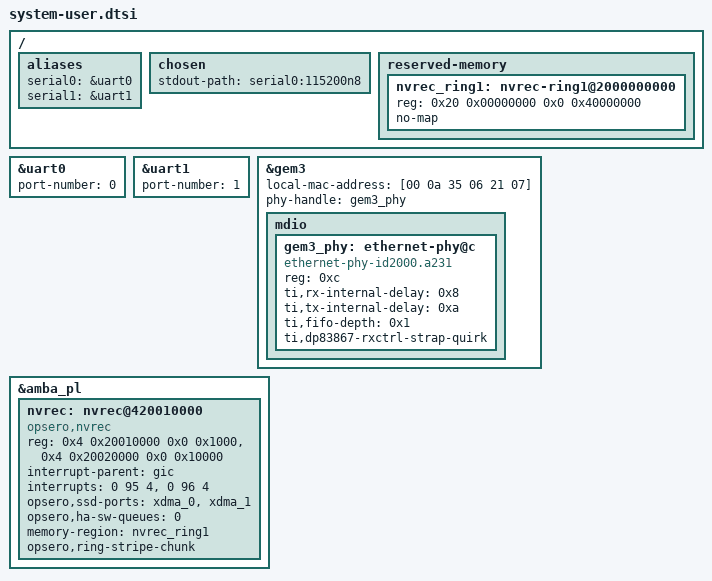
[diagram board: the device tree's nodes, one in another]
// SPDX-License-Identifier: MIT
// Copyright (C) 2025-2026, Opsero Electronic Design Inc.  All rights reserved.

/*
 * SoC-side board fixups, layered on top of the gen-machineconf /
 * lopper-generated cortexa53-linux.dts (which already carries the PS config
 * and the PL xilinx_xdma PCIe node(s) from the XSA).
 *
 * UART (ttyPS console):
 *   The 2025.2 lopper/gen-machineconf flow emits port-number = <0> on BOTH
 *   uart0 (ff000000) and uart1 (ff010000), so the ttyPS0/ttyPS1 assignment is
 *   left to probe order. This board's console is on psu_uart_0, so pin the
 *   port numbers (and serial aliases) explicitly. Mirrors the PetaLinux BSPs.
 *
 * Note: unlike the ZCU104, this board's SD interface sustains UHS modes (the
 * PetaLinux BSP needs no sdhci cap), so no SD override is applied here.
 */

&uart0 {
   port-number = <0>;
};

&uart1 {
   port-number = <1>;
};

/ {
   aliases {
      serial0 = &uart0;
      serial1 = &uart1;
   };
   chosen {
      stdout-path = "serial0:115200n8";
   };
};

/* PS GEM3 (board RJ45): the SDT flow does not describe the board-level
 * TI DP83867 PHY, so Linux falls back to the Generic PHY driver and the
 * RGMII clock delays are never programmed - the link negotiates 1G but
 * passes no packets. Values from the official zynqmp-zcu106-revA.dts
 * (PHY at MDIO address 0xc). The fixed MAC replaces the random one the
 * SDT flow leaves us with, keeping DHCP leases stable across boots.
 */
&gem3 {
	local-mac-address = [00 0a 35 06 21 07];
	phy-handle = <&gem3_phy>;
	mdio {
		#address-cells = <1>;
		#size-cells = <0>;
		gem3_phy: ethernet-phy@c {
			compatible = "ethernet-phy-id2000.a231";
			reg = <0xc>;
			ti,rx-internal-delay = <0x8>;
			ti,tx-internal-delay = <0xa>;
			ti,fifo-depth = <0x1>;
			ti,dp83867-rxctrl-strap-quirk;
		};
	};
};

/*
 * FPGA Drive NVMe-offload recorder: the nvrec kernel driver (Yocto/meta-nvrec,
 * sw/nvrec-driver) drives nvrec_core AND the NVMe Host Accelerator through ONE
 * node, so the addresses of both IPs are listed here (include/nvrec_regs.h,
 * zcu106_hpc0 address map):
 *   core     nvrec_core registers           0x4_2001_0000, 4 KB
 *   ha-lite  nvmeha S_AXI_LITE registers    0x4_2002_0000, 64 KB
 *   irq core nvrec_core irq   pl_ps_irq0[6] -> GIC SPI 95
 *   irq ha   ha_interrupt     pl_ps_irq0[7] -> GIC SPI 96
 * The SDT also emits generic nodes for the two IPs (no Linux driver binds
 * them). opsero,ssd-ports lists the PL root ports in SSD order: xdma_0 =
 * SSD1 = nvmeha SSD 0, xdma_1 = SSD2 = nvmeha SSD 1; an NVMe SSD behind any
 * other root port is left to the stock nvme driver.
 * The Host Accelerator is built with HARDWARE-ONLY queues (register map 1.0
 * rev b: no S_AXI software queue window, the hardware SQ/CQ is NVMe QID 1,
 * all CPU I/O goes through the nvrec command injector):
 * opsero,ha-sw-queues = <0> says so explicitly.
 * The other nvmeha build parameters and the queue window come from nvrec_regs.h;
 * the opsero,ha-* properties (driver.md) override them without a rebuild.
 * If the block design changes the address map or the interrupt bits, change
 * this node with it.
 *
 * Split ring (register map 1.3, driver 1.2): nvrec_core's second ring port
 * reaches the soldered 2 GB PL DDR4 through a DDR4 controller in the PL, at
 * 0x20_0000_0000, mapped for the ring port and the XDMA root ports only --
 * the PS has no path to it and no memory node covers it. memory-region
 * reserves its first 1 GB for ring B (no-map: the kernel never maps or
 * allocates it); ring A stays in the CMA pool (cma=, PS DDR4). The driver
 * refuses a split ring while the controller is not calibrated
 * (STATE.MEM1_READY). opsero,ring-stripe-chunk makes the board's default
 * stripe the whole chunk (driver module parameter stripe_kb and the apps'
 * --stripe override it): measured on this board (Sabrent RAID0, Gen3 x4), whole
 * chunks play back best (5500 MB/s sustained vs 5250 with 4 KB / 64 KB stripes;
 * 6000 at MaxPayload 256) and record 6000 MB/s at MaxPayload 256, while 64 KB
 * was the worst layout in every SSD playback test. The in-order ring
 * writer/reader alternates between HP2 (~5.15 GB/s) and the PL DDR4 (~7.8
 * GB/s), so any stripe sits near their harmonic mean (~6.2 GB/s); whole chunks
 * keep each SSD command in one memory.
 */
/ {
   reserved-memory {
      #address-cells = <2>;
      #size-cells = <2>;
      ranges;

      nvrec_ring1: nvrec-ring1@2000000000 {
         reg = <0x20 0x00000000 0x0 0x40000000>;
         no-map;
      };
   };
};

&amba_pl {
   nvrec: nvrec@420010000 {
      compatible = "opsero,nvrec";
      reg = <0x4 0x20010000 0x0 0x1000>,
            <0x4 0x20020000 0x0 0x10000>;
      reg-names = "core", "ha-lite";
      interrupt-parent = <&gic>;
      interrupts = <0 95 4>, <0 96 4>;
      interrupt-names = "core", "ha";
      opsero,ssd-ports = <&xdma_0>, <&xdma_1>;
      opsero,ha-sw-queues = <0>;
      memory-region = <&nvrec_ring1>;
      opsero,ring-stripe-chunk;
   };
};
